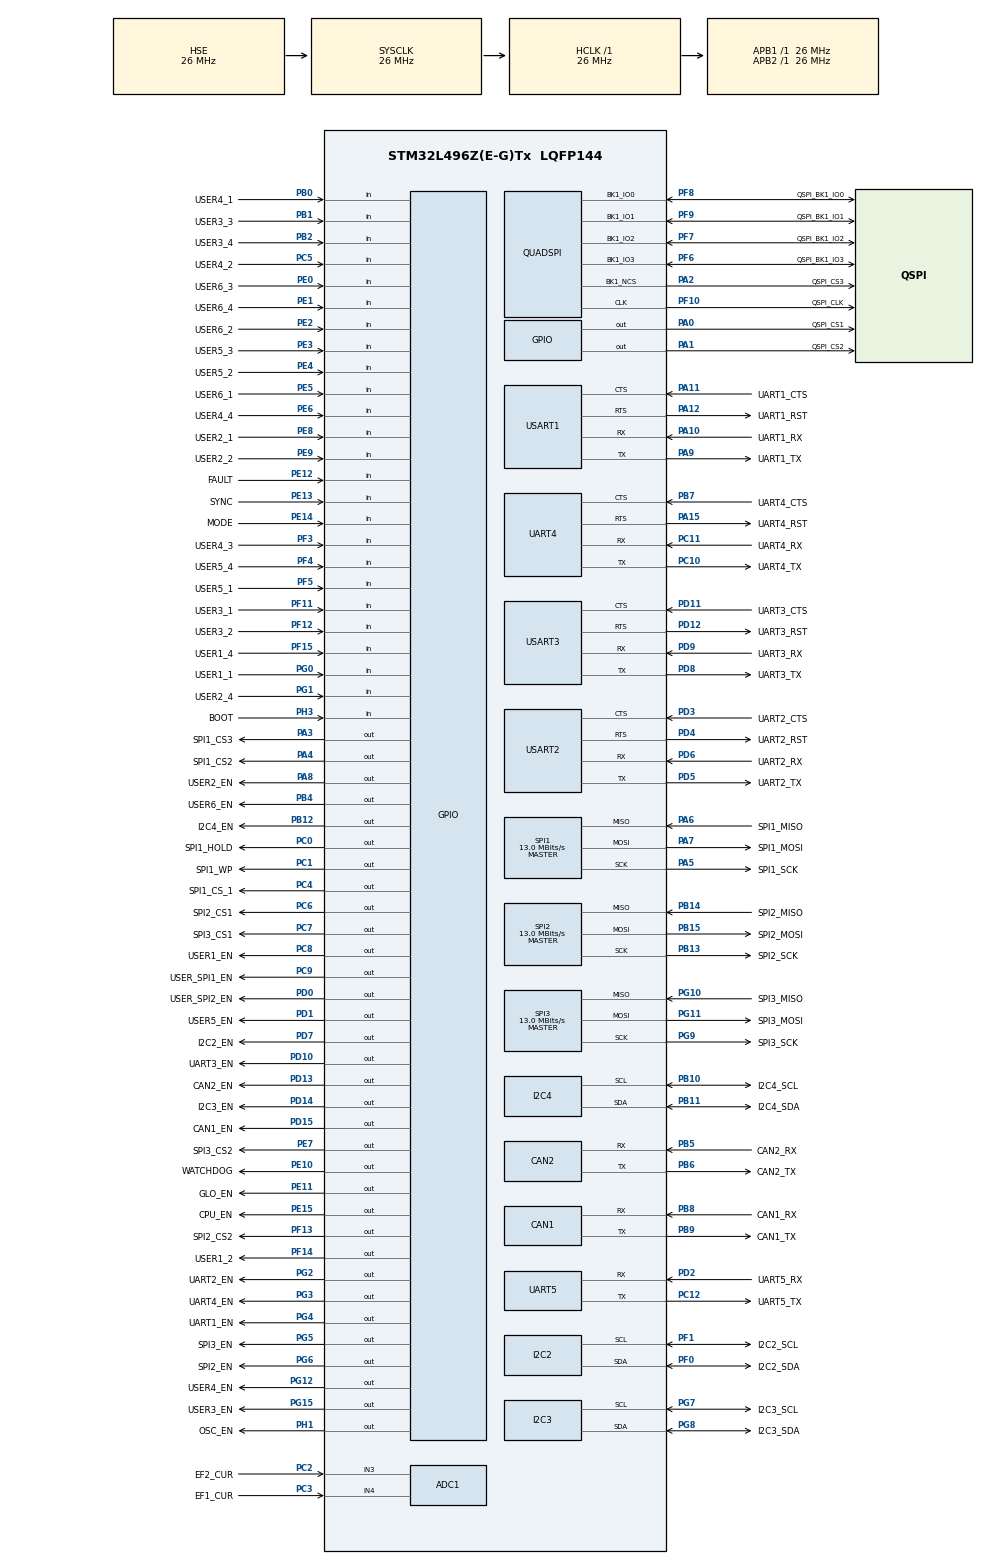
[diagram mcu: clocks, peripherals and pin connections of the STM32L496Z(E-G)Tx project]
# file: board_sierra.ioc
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ADC1.Channel-1\#ChannelRegularConversion=ADC_CHANNEL_3
ADC1.NbrOfConversionFlag=1
ADC1.OffsetNumber-1\#ChannelRegularConversion=ADC_OFFSET_NONE
ADC1.Rank-1\#ChannelRegularConversion=1
ADC1.SamplingTime-1\#ChannelRegularConversion=ADC_SAMPLETIME_2CYCLES_5
ADC1.master=1
CAN1.BS1=CAN_BS1_10TQ
CAN1.BS2=CAN_BS2_1TQ
CAN1.CalculateTimeQuantum=615.3846153846154
CAN2.BS1=CAN_BS1_10TQ
CAN2.BS2=CAN_BS2_1TQ
CAN2.CalculateTimeQuantum=615.3846153846154
I2C2.Timing=0x00606497
I2C3.Timing=0x00606497
I2C4.Timing=0x00606497
Mcu.Family=STM32L4
Mcu.Name=STM32L496Z(E-G)Tx
Mcu.Package=LQFP144
NVIC.PriorityGroup=NVIC_PRIORITYGROUP_4
PA0.GPIO_Label=QSPI_CS1
PA0.Signal=GPIO_Output
PA1.GPIO_Label=QSPI_CS2
PA1.Signal=GPIO_Output
PA10.GPIO_Label=UART1_RX
PA10.Mode=Asynchronous
PA10.Signal=USART1_RX
PA11.GPIO_Label=UART1_CTS
PA11.Mode=CTS_RTS
PA11.Signal=USART1_CTS
PA12.GPIO_Label=UART1_RST
PA12.Mode=CTS_RTS
PA12.Signal=USART1_RTS
PA13\ (JTMS/SWDIO).GPIO_Label=SW_DIO
PA13\ (JTMS/SWDIO).Mode=Trace_Asynchronous_SW
PA13\ (JTMS/SWDIO).Signal=SYS_JTMS-SWDIO
PA14\ (JTCK/SWCLK).GPIO_Label=SW_CLK
PA14\ (JTCK/SWCLK).Mode=Trace_Asynchronous_SW
PA14\ (JTCK/SWCLK).Signal=SYS_JTCK-SWCLK
PA15\ (JTDI).GPIO_Label=UART4_RST
PA15\ (JTDI).Mode=CTS_RTS
PA15\ (JTDI).Signal=UART4_RTS
PA2.GPIO_Label=QSPI_CS3
PA2.Mode=Single Bank 1
PA2.Signal=QUADSPI_BK1_NCS
PA3.GPIO_Label=SPI1_CS3
PA3.Signal=GPIO_Output
PA4.GPIO_Label=SPI1_CS2
PA4.Signal=GPIO_Output
PA5.GPIO_Label=SPI1_SCK
PA5.Mode=Full_Duplex_Master
PA5.Signal=SPI1_SCK
PA6.GPIO_Label=SPI1_MISO
PA6.Mode=Full_Duplex_Master
PA6.Signal=SPI1_MISO
PA7.GPIO_Label=SPI1_MOSI
PA7.Mode=Full_Duplex_Master
PA7.Signal=SPI1_MOSI
PA8.GPIO_Label=USER2_EN
PA8.Signal=GPIO_Output
PA9.GPIO_Label=UART1_TX
PA9.Mode=Asynchronous
PA9.Signal=USART1_TX
PB0.GPIO_Label=USER4_1
PB0.Signal=GPIO_Input
PB1.GPIO_Label=USER3_3
PB1.Signal=GPIO_Input
PB10.GPIO_Label=I2C4_SCL
PB10.Mode=I2C
PB10.Signal=I2C4_SCL
PB11.GPIO_Label=I2C4_SDA
PB11.Mode=I2C
PB11.Signal=I2C4_SDA
PB12.GPIO_Label=I2C4_EN
PB12.Signal=GPIO_Output
PB13.GPIO_Label=SPI2_SCK
PB13.Mode=Full_Duplex_Master
PB13.Signal=SPI2_SCK
PB14.GPIO_Label=SPI2_MISO
PB14.Mode=Full_Duplex_Master
PB14.Signal=SPI2_MISO
PB15.GPIO_Label=SPI2_MOSI
PB15.Mode=Full_Duplex_Master
PB15.Signal=SPI2_MOSI
PB2.GPIO_Label=USER3_4
PB2.Signal=GPIO_Input
PB3\ (JTDO/TRACESWO).GPIO_Label=SW_O
PB3\ (JTDO/TRACESWO).Mode=Trace_Asynchronous_SW
PB3\ (JTDO/TRACESWO).Signal=SYS_JTDO-SWO
PB4\ (NJTRST).GPIO_Label=USER6_EN
PB4\ (NJTRST).Signal=GPIO_Output
PB5.GPIO_Label=CAN2_RX
PB5.Mode=Slave
PB5.Signal=CAN2_RX
PB6.GPIO_Label=CAN2_TX
PB6.Mode=Slave
PB6.Signal=CAN2_TX
PB7.GPIO_Label=UART4_CTS
PB7.Mode=CTS_RTS
PB7.Signal=UART4_CTS
PB8.GPIO_Label=CAN1_RX
PB8.Mode=Master
PB8.Signal=CAN1_RX
PB9.GPIO_Label=CAN1_TX
PB9.Mode=Master
PB9.Signal=CAN1_TX
PC0.GPIO_Label=SPI1_HOLD
PC0.Signal=GPIO_Output
PC1.GPIO_Label=SPI1_WP
PC1.Signal=GPIO_Output
PC10.GPIO_Label=UART4_TX
PC10.Mode=Asynchronous
PC10.Signal=UART4_TX
PC11.GPIO_Label=UART4_RX
PC11.Mode=Asynchronous
PC11.Signal=UART4_RX
PC12.GPIO_Label=UART5_TX
PC12.Mode=Asynchronous
PC12.Signal=UART5_TX
PC14-OSC32_IN\ (PC14).GPIO_Label=OSC32_IN
PC14-OSC32_IN\ (PC14).Mode=LSE-External-Oscillator
PC14-OSC32_IN\ (PC14).Signal=RCC_OSC32_IN
PC15-OSC32_OUT\ (PC15).GPIO_Label=OSC32_OUT
PC15-OSC32_OUT\ (PC15).Mode=LSE-External-Oscillator
PC15-OSC32_OUT\ (PC15).Signal=RCC_OSC32_OUT
PC2.GPIO_Label=EF2_CUR
PC2.Signal=ADCx_IN3
PC3.GPIO_Label=EF1_CUR
PC3.Signal=ADCx_IN4
PC4.GPIO_Label=SPI1_CS_1
PC4.Signal=GPIO_Output
PC5.GPIO_Label=USER4_2
PC5.Signal=GPIO_Input
PC6.GPIO_Label=SPI2_CS1
PC6.Signal=GPIO_Output
PC7.GPIO_Label=SPI3_CS1
PC7.Signal=GPIO_Output
PC8.GPIO_Label=USER1_EN
PC8.Signal=GPIO_Output
PC9.GPIO_Label=USER_SPI1_EN
PC9.Signal=GPIO_Output
PD0.GPIO_Label=USER_SPI2_EN
PD0.Signal=GPIO_Output
PD1.GPIO_Label=USER5_EN
PD1.Signal=GPIO_Output
PD10.GPIO_Label=UART3_EN
PD10.Signal=GPIO_Output
PD11.GPIO_Label=UART3_CTS
PD11.Mode=CTS_RTS
PD11.Signal=USART3_CTS
PD12.GPIO_Label=UART3_RST
PD12.Mode=CTS_RTS
PD12.Signal=USART3_RTS
PD13.GPIO_Label=CAN2_EN
PD13.Signal=GPIO_Output
PD14.GPIO_Label=I2C3_EN
PD14.Signal=GPIO_Output
PD15.GPIO_Label=CAN1_EN
PD15.Signal=GPIO_Output
PD2.GPIO_Label=UART5_RX
PD2.Mode=Asynchronous
PD2.Signal=UART5_RX
PD3.GPIO_Label=UART2_CTS
PD3.Mode=CTS_RTS
PD3.Signal=USART2_CTS
PD4.GPIO_Label=UART2_RST
PD4.Mode=CTS_RTS
PD4.Signal=USART2_RTS
PD5.GPIO_Label=UART2_TX
PD5.Mode=Asynchronous
PD5.Signal=USART2_TX
PD6.GPIO_Label=UART2_RX
PD6.Mode=Asynchronous
PD6.Signal=USART2_RX
PD7.GPIO_Label=I2C2_EN
PD7.Signal=GPIO_Output
PD8.GPIO_Label=UART3_TX
PD8.Mode=Asynchronous
PD8.Signal=USART3_TX
PD9.GPIO_Label=UART3_RX
PD9.Mode=Asynchronous
PD9.Signal=USART3_RX
PE0.GPIO_Label=USER6_3
PE0.Signal=GPIO_Input
PE1.GPIO_Label=USER6_4
PE1.Signal=GPIO_Input
PE10.GPIO_Label=WATCHDOG
PE10.Signal=GPIO_Output
PE11.GPIO_Label=GLO_EN
PE11.Signal=GPIO_Output
PE12.GPIO_Label=FAULT
PE12.Signal=GPIO_Input
PE13.GPIO_Label=SYNC
PE13.Signal=GPIO_Input
PE14.GPIO_Label=MODE
PE14.Signal=GPIO_Input
PE15.GPIO_Label=CPU_EN
PE15.Signal=GPIO_Output
PE2.GPIO_Label=USER6_2
PE2.Signal=GPIO_Input
PE3.GPIO_Label=USER5_3
PE3.Signal=GPIO_Input
PE4.GPIO_Label=USER5_2
PE4.Signal=GPIO_Input
PE5.GPIO_Label=USER6_1
PE5.Signal=GPIO_Input
PE6.GPIO_Label=USER4_4
PE6.Signal=GPIO_Input
PE7.GPIO_Label=SPI3_CS2
PE7.Signal=GPIO_Output
PE8.GPIO_Label=USER2_1
PE8.Signal=GPIO_Input
PE9.GPIO_Label=USER2_2
PE9.Signal=GPIO_Input
PF0.GPIO_Label=I2C2_SDA
PF0.Mode=I2C
PF0.Signal=I2C2_SDA
PF1.GPIO_Label=I2C2_SCL
PF1.Mode=I2C
PF1.Signal=I2C2_SCL
PF10.GPIO_Label=QSPI_CLK
PF10.Mode=Single Bank 1
PF10.Signal=QUADSPI_CLK
PF11.GPIO_Label=USER3_1
PF11.Signal=GPIO_Input
PF12.GPIO_Label=USER3_2
PF12.Signal=GPIO_Input
PF13.GPIO_Label=SPI2_CS2
PF13.Signal=GPIO_Output
PF14.GPIO_Label=USER1_2
PF14.GPIO_Speed=GPIO_SPEED_FREQ_LOW
PF14.PinState=GPIO_PIN_RESET
PF14.Signal=GPIO_Output
PF15.GPIO_Label=USER1_4
PF15.Signal=GPIO_Input
PF3.GPIO_Label=USER4_3
PF3.Signal=GPIO_Input
PF4.GPIO_Label=USER5_4
PF4.Signal=GPIO_Input
PF5.GPIO_Label=USER5_1
PF5.Signal=GPIO_Input
PF6.GPIO_Label=QSPI_BK1_IO3
PF6.Mode=Single Bank 1
PF6.Signal=QUADSPI_BK1_IO3
PF7.GPIO_Label=QSPI_BK1_IO2
PF7.Mode=Single Bank 1
PF7.Signal=QUADSPI_BK1_IO2
PF8.GPIO_Label=QSPI_BK1_IO0
PF8.Mode=Single Bank 1
PF8.Signal=QUADSPI_BK1_IO0
PF9.GPIO_Label=QSPI_BK1_IO1
PF9.Mode=Single Bank 1
PF9.Signal=QUADSPI_BK1_IO1
PG0.GPIO_Label=USER1_1
PG0.Signal=GPIO_Input
PG1.GPIO_Label=USER2_4
PG1.Signal=GPIO_Input
PG10.GPIO_Label=SPI3_MISO
PG10.Mode=Full_Duplex_Master
PG10.Signal=SPI3_MISO
PG11.GPIO_Label=SPI3_MOSI
PG11.Mode=Full_Duplex_Master
PG11.Signal=SPI3_MOSI
PG12.GPIO_Label=USER4_EN
PG12.Signal=GPIO_Output
PG15.GPIO_Label=USER3_EN
PG15.Signal=GPIO_Output
PG2.GPIO_Label=UART2_EN
PG2.Signal=GPIO_Output
PG3.GPIO_Label=UART4_EN
PG3.Signal=GPIO_Output
PG4.GPIO_Label=UART1_EN
PG4.Signal=GPIO_Output
PG5.GPIO_Label=SPI3_EN
PG5.Signal=GPIO_Output
PG6.GPIO_Label=SPI2_EN
PG6.Signal=GPIO_Output
PG7.GPIO_Label=I2C3_SCL
PG7.Mode=I2C
PG7.Signal=I2C3_SCL
PG8.GPIO_Label=I2C3_SDA
PG8.Mode=I2C
PG8.Signal=I2C3_SDA
PG9.GPIO_Label=SPI3_SCK
PG9.Mode=Full_Duplex_Master
PG9.Signal=SPI3_SCK
PH0-OSC_IN\ (PH0).GPIO_Label=OSC_IN
PH0-OSC_IN\ (PH0).Mode=HSE-External-Clock-Source
PH0-OSC_IN\ (PH0).Signal=RCC_OSC_IN
PH1-OSC_OUT\ (PH1).GPIO_Label=OSC_EN
PH1-OSC_OUT\ (PH1).GPIO_PuPd=GPIO_PULLUP
PH1-OSC_OUT\ (PH1).PinState=GPIO_PIN_SET
PH1-OSC_OUT\ (PH1).Signal=GPIO_Output
PH3-BOOT0.GPIO_Label=BOOT
PH3-BOOT0.Signal=GPIO_Input
ProjectManager.HeapSize=0x200
ProjectManager.StackSize=0x400
ProjectManager.TargetToolchain=STM32CubeIDE
RCC.ADCFreq_Value=64000000
RCC.AHBFreq_Value=26000000
RCC.APB1Freq_Value=26000000
RCC.APB1TimFreq_Value=26000000
RCC.APB2Freq_Value=26000000
RCC.APB2TimFreq_Value=26000000
RCC.CortexFreq_Value=26000000
RCC.HCLKFreq_Value=26000000
RCC.HSE_VALUE=26000000
RCC.HSI48_VALUE=48000000
RCC.HSI_VALUE=16000000
RCC.MSI_VALUE=4000000
RCC.PLLN=12
RCC.PLLR=RCC_PLLR_DIV4
RCC.PLLSAI1N=16
RCC.PLLSAI1R=RCC_PLLR_DIV4
RCC.PLLSourceVirtual=RCC_PLLSOURCE_HSI
RCC.SYSCLKFreq_VALUE=26000000
RCC.SYSCLKSource=RCC_SYSCLKSOURCE_HSE
RCC.USBFreq_Value=128000000
RCC.VCOOutputFreq_Value=192000000
SH.ADCx_IN3.0=ADC1_IN3,IN3-Single-Ended
SH.ADCx_IN4.0=ADC1_IN4,IN4-Single-Ended
SPI1.BaudRatePrescaler=SPI_BAUDRATEPRESCALER_2
SPI1.CalculateBaudRate=13.0 MBits/s
SPI1.Direction=SPI_DIRECTION_2LINES
SPI1.Mode=SPI_MODE_MASTER
SPI1.VirtualType=VM_MASTER
SPI2.BaudRatePrescaler=SPI_BAUDRATEPRESCALER_2
SPI2.CalculateBaudRate=13.0 MBits/s
SPI2.Direction=SPI_DIRECTION_2LINES
SPI2.Mode=SPI_MODE_MASTER
SPI2.VirtualType=VM_MASTER
SPI3.BaudRatePrescaler=SPI_BAUDRATEPRESCALER_2
SPI3.CalculateBaudRate=13.0 MBits/s
SPI3.Direction=SPI_DIRECTION_2LINES
SPI3.Mode=SPI_MODE_MASTER
SPI3.VirtualType=VM_MASTER
USART1.VirtualMode-Asynchronous=VM_ASYNC
USART2.VirtualMode-Asynchronous=VM_ASYNC
USART3.VirtualMode-Asynchronous=VM_ASYNC
VP_RCC_LSE.Mode=CRS SYNC Source LSE
VP_SYS_V_PVD_IN.Mode=Mode_PVD_Int
board=custom

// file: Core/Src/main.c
/* USER CODE BEGIN Header */
/**
  ******************************************************************************
  * @file           : main.c
  * @brief          : Main program body
  ******************************************************************************
  * @attention
  *
  * <h2><center>&copy; Copyright (c) 2020 STMicroelectronics.
  * All rights reserved.</center></h2>
  *
  * This software component is licensed by ST under BSD 3-Clause license,
  * the "License"; You may not use this file except in compliance with the
  * License. You may obtain a copy of the License at:
  *                        opensource.org/licenses/BSD-3-Clause
  *
  ******************************************************************************
  */
/* USER CODE END Header */

#include "main.h"

ADC_HandleTypeDef hadc1;

CAN_HandleTypeDef hcan1;
CAN_HandleTypeDef hcan2;

I2C_HandleTypeDef hi2c2;
I2C_HandleTypeDef hi2c3;
I2C_HandleTypeDef hi2c4;

QSPI_HandleTypeDef hqspi;

SPI_HandleTypeDef hspi1;
SPI_HandleTypeDef hspi2;
SPI_HandleTypeDef hspi3;

UART_HandleTypeDef huart4;
UART_HandleTypeDef huart5;
UART_HandleTypeDef huart1;
UART_HandleTypeDef huart2;
UART_HandleTypeDef huart3;

void SystemClock_Config(void);
static void MX_GPIO_Init(void);
static void MX_ADC1_Init(void);
static void MX_CAN1_Init(void);
static void MX_CAN2_Init(void);
static void MX_I2C2_Init(void);
static void MX_I2C3_Init(void);
static void MX_I2C4_Init(void);
static void MX_QUADSPI_Init(void);
static void MX_SPI1_Init(void);
static void MX_SPI2_Init(void);
static void MX_SPI3_Init(void);
static void MX_UART4_Init(void);
static void MX_UART5_Init(void);
static void MX_USART1_UART_Init(void);
static void MX_USART2_UART_Init(void);
static void MX_USART3_UART_Init(void);

int main(void)
{

  /* MCU Configuration--------------------------------------------------------*/

  /* Reset of all peripherals, Initializes the Flash interface and the Systick. */
  HAL_Init();

  /* Configure the system clock */
  SystemClock_Config();

  /* Initialize all configured peripherals */
  MX_GPIO_Init();
  MX_ADC1_Init();
  MX_CAN1_Init();
  MX_CAN2_Init();
  MX_I2C2_Init();
  MX_I2C3_Init();
  MX_I2C4_Init();
  MX_QUADSPI_Init();
  MX_SPI1_Init();
  MX_SPI2_Init();
  MX_SPI3_Init();
  MX_UART4_Init();
  MX_UART5_Init();
  MX_USART1_UART_Init();
  MX_USART2_UART_Init();
  MX_USART3_UART_Init();
  /* USER CODE BEGIN 2 */

  // turn on isolator for USER1
  HAL_GPIO_WritePin(GPIOC, USER1_EN_Pin, GPIO_PIN_SET);

  /* USER CODE END 2 */

  /* Infinite loop */
  /* USER CODE BEGIN WHILE */
  while (1)
  {

	  HAL_GPIO_TogglePin(GPIOF, USER1_2_Pin);
	  HAL_Delay(200);

    /* USER CODE END WHILE */

  }
}

void SystemClock_Config(void)
{
  RCC_OscInitTypeDef RCC_OscInitStruct = {0};
  RCC_ClkInitTypeDef RCC_ClkInitStruct = {0};
  RCC_PeriphCLKInitTypeDef PeriphClkInit = {0};
  RCC_CRSInitTypeDef RCC_CRSInitStruct = {0};

  /** Initializes the CPU, AHB and APB busses clocks
  */
  RCC_OscInitStruct.OscillatorType = RCC_OSCILLATORTYPE_HSI|RCC_OSCILLATORTYPE_HSE;
  RCC_OscInitStruct.HSEState = RCC_HSE_BYPASS;
  RCC_OscInitStruct.HSIState = RCC_HSI_ON;
  RCC_OscInitStruct.HSICalibrationValue = RCC_HSICALIBRATION_DEFAULT;
  RCC_OscInitStruct.PLL.PLLState = RCC_PLL_NONE;
  if (HAL_RCC_OscConfig(&RCC_OscInitStruct) != HAL_OK)
  {
    Error_Handler();
  }
  /** Initializes the CPU, AHB and APB busses clocks
  */
  RCC_ClkInitStruct.ClockType = RCC_CLOCKTYPE_HCLK|RCC_CLOCKTYPE_SYSCLK
                              |RCC_CLOCKTYPE_PCLK1|RCC_CLOCKTYPE_PCLK2;
  RCC_ClkInitStruct.SYSCLKSource = RCC_SYSCLKSOURCE_HSE;
  RCC_ClkInitStruct.AHBCLKDivider = RCC_SYSCLK_DIV1;
  RCC_ClkInitStruct.APB1CLKDivider = RCC_HCLK_DIV1;
  RCC_ClkInitStruct.APB2CLKDivider = RCC_HCLK_DIV1;

  if (HAL_RCC_ClockConfig(&RCC_ClkInitStruct, FLASH_LATENCY_1) != HAL_OK)
  {
    Error_Handler();
  }
  PeriphClkInit.PeriphClockSelection = RCC_PERIPHCLK_USART1|RCC_PERIPHCLK_USART2
                              |RCC_PERIPHCLK_USART3|RCC_PERIPHCLK_UART4
                              |RCC_PERIPHCLK_UART5|RCC_PERIPHCLK_I2C2
                              |RCC_PERIPHCLK_I2C3|RCC_PERIPHCLK_I2C4
                              |RCC_PERIPHCLK_ADC;
  PeriphClkInit.Usart1ClockSelection = RCC_USART1CLKSOURCE_PCLK2;
  PeriphClkInit.Usart2ClockSelection = RCC_USART2CLKSOURCE_PCLK1;
  PeriphClkInit.Usart3ClockSelection = RCC_USART3CLKSOURCE_PCLK1;
  PeriphClkInit.Uart4ClockSelection = RCC_UART4CLKSOURCE_PCLK1;
  PeriphClkInit.Uart5ClockSelection = RCC_UART5CLKSOURCE_PCLK1;
  PeriphClkInit.I2c2ClockSelection = RCC_I2C2CLKSOURCE_PCLK1;
  PeriphClkInit.I2c3ClockSelection = RCC_I2C3CLKSOURCE_PCLK1;
  PeriphClkInit.I2c4ClockSelection = RCC_I2C4CLKSOURCE_PCLK1;
  PeriphClkInit.AdcClockSelection = RCC_ADCCLKSOURCE_PLLSAI1;
  PeriphClkInit.PLLSAI1.PLLSAI1Source = RCC_PLLSOURCE_HSI;
  PeriphClkInit.PLLSAI1.PLLSAI1M = 1;
  PeriphClkInit.PLLSAI1.PLLSAI1N = 16;
  PeriphClkInit.PLLSAI1.PLLSAI1P = RCC_PLLP_DIV2;
  PeriphClkInit.PLLSAI1.PLLSAI1Q = RCC_PLLQ_DIV2;
  PeriphClkInit.PLLSAI1.PLLSAI1R = RCC_PLLR_DIV4;
  PeriphClkInit.PLLSAI1.PLLSAI1ClockOut = RCC_PLLSAI1_ADC1CLK;
  if (HAL_RCCEx_PeriphCLKConfig(&PeriphClkInit) != HAL_OK)
  {
    Error_Handler();
  }
  /** Configure the main internal regulator output voltage
  */
  if (HAL_PWREx_ControlVoltageScaling(PWR_REGULATOR_VOLTAGE_SCALE1) != HAL_OK)
  {
    Error_Handler();
  }
  /** Enable the SYSCFG APB clock
  */
  __HAL_RCC_CRS_CLK_ENABLE();
  /** Configures CRS
  */
  RCC_CRSInitStruct.Prescaler = RCC_CRS_SYNC_DIV1;
  RCC_CRSInitStruct.Source = RCC_CRS_SYNC_SOURCE_LSE;
  RCC_CRSInitStruct.Polarity = RCC_CRS_SYNC_POLARITY_RISING;
  RCC_CRSInitStruct.ReloadValue = __HAL_RCC_CRS_RELOADVALUE_CALCULATE(48000000,32768);
  RCC_CRSInitStruct.ErrorLimitValue = 34;
  RCC_CRSInitStruct.HSI48CalibrationValue = 32;

  HAL_RCCEx_CRSConfig(&RCC_CRSInitStruct);
}

static void MX_ADC1_Init(void)
{

  ADC_MultiModeTypeDef multimode = {0};
  ADC_ChannelConfTypeDef sConfig = {0};

  /** Common config
  */
  hadc1.Instance = ADC1;
  hadc1.Init.ClockPrescaler = ADC_CLOCK_ASYNC_DIV1;
  hadc1.Init.Resolution = ADC_RESOLUTION_12B;
  hadc1.Init.DataAlign = ADC_DATAALIGN_RIGHT;
  hadc1.Init.ScanConvMode = ADC_SCAN_DISABLE;
  hadc1.Init.EOCSelection = ADC_EOC_SINGLE_CONV;
  hadc1.Init.LowPowerAutoWait = DISABLE;
  hadc1.Init.ContinuousConvMode = DISABLE;
  hadc1.Init.NbrOfConversion = 1;
  hadc1.Init.DiscontinuousConvMode = DISABLE;
  hadc1.Init.NbrOfDiscConversion = 1;
  hadc1.Init.ExternalTrigConv = ADC_SOFTWARE_START;
  hadc1.Init.ExternalTrigConvEdge = ADC_EXTERNALTRIGCONVEDGE_NONE;
  hadc1.Init.DMAContinuousRequests = DISABLE;
  hadc1.Init.Overrun = ADC_OVR_DATA_PRESERVED;
  hadc1.Init.OversamplingMode = DISABLE;
  if (HAL_ADC_Init(&hadc1) != HAL_OK)
  {
    Error_Handler();
  }
  /** Configure the ADC multi-mode
  */
  multimode.Mode = ADC_MODE_INDEPENDENT;
  if (HAL_ADCEx_MultiModeConfigChannel(&hadc1, &multimode) != HAL_OK)
  {
    Error_Handler();
  }
  /** Configure Regular Channel
  */
  sConfig.Channel = ADC_CHANNEL_3;
  sConfig.Rank = ADC_REGULAR_RANK_1;
  sConfig.SamplingTime = ADC_SAMPLETIME_2CYCLES_5;
  sConfig.SingleDiff = ADC_SINGLE_ENDED;
  sConfig.OffsetNumber = ADC_OFFSET_NONE;
  sConfig.Offset = 0;
  if (HAL_ADC_ConfigChannel(&hadc1, &sConfig) != HAL_OK)
  {
    Error_Handler();
  }

}

static void MX_CAN1_Init(void)
{

  hcan1.Instance = CAN1;
  hcan1.Init.Prescaler = 16;
  hcan1.Init.Mode = CAN_MODE_NORMAL;
  hcan1.Init.SyncJumpWidth = CAN_SJW_1TQ;
  hcan1.Init.TimeSeg1 = CAN_BS1_10TQ;
  hcan1.Init.TimeSeg2 = CAN_BS2_1TQ;
  hcan1.Init.TimeTriggeredMode = DISABLE;
  hcan1.Init.AutoBusOff = DISABLE;
  hcan1.Init.AutoWakeUp = DISABLE;
  hcan1.Init.AutoRetransmission = DISABLE;
  hcan1.Init.ReceiveFifoLocked = DISABLE;
  hcan1.Init.TransmitFifoPriority = DISABLE;
  if (HAL_CAN_Init(&hcan1) != HAL_OK)
  {
    Error_Handler();
  }

}

static void MX_CAN2_Init(void)
{

  hcan2.Instance = CAN2;
  hcan2.Init.Prescaler = 16;
  hcan2.Init.Mode = CAN_MODE_NORMAL;
  hcan2.Init.SyncJumpWidth = CAN_SJW_1TQ;
  hcan2.Init.TimeSeg1 = CAN_BS1_10TQ;
  hcan2.Init.TimeSeg2 = CAN_BS2_1TQ;
  hcan2.Init.TimeTriggeredMode = DISABLE;
  hcan2.Init.AutoBusOff = DISABLE;
  hcan2.Init.AutoWakeUp = DISABLE;
  hcan2.Init.AutoRetransmission = DISABLE;
  hcan2.Init.ReceiveFifoLocked = DISABLE;
  hcan2.Init.TransmitFifoPriority = DISABLE;
  if (HAL_CAN_Init(&hcan2) != HAL_OK)
  {
    Error_Handler();
  }

}

static void MX_I2C2_Init(void)
{

  hi2c2.Instance = I2C2;
  hi2c2.Init.Timing = 0x00606497;
  hi2c2.Init.OwnAddress1 = 0;
  hi2c2.Init.AddressingMode = I2C_ADDRESSINGMODE_7BIT;
  hi2c2.Init.DualAddressMode = I2C_DUALADDRESS_DISABLE;
  hi2c2.Init.OwnAddress2 = 0;
  hi2c2.Init.OwnAddress2Masks = I2C_OA2_NOMASK;
  hi2c2.Init.GeneralCallMode = I2C_GENERALCALL_DISABLE;
  hi2c2.Init.NoStretchMode = I2C_NOSTRETCH_DISABLE;
  if (HAL_I2C_Init(&hi2c2) != HAL_OK)
  {
    Error_Handler();
  }
  /** Configure Analogue filter
  */
  if (HAL_I2CEx_ConfigAnalogFilter(&hi2c2, I2C_ANALOGFILTER_ENABLE) != HAL_OK)
  {
    Error_Handler();
  }
  /** Configure Digital filter
  */
  if (HAL_I2CEx_ConfigDigitalFilter(&hi2c2, 0) != HAL_OK)
  {
    Error_Handler();
  }

}

static void MX_I2C3_Init(void)
{

  hi2c3.Instance = I2C3;
  hi2c3.Init.Timing = 0x00606497;
  hi2c3.Init.OwnAddress1 = 0;
  hi2c3.Init.AddressingMode = I2C_ADDRESSINGMODE_7BIT;
  hi2c3.Init.DualAddressMode = I2C_DUALADDRESS_DISABLE;
  hi2c3.Init.OwnAddress2 = 0;
  hi2c3.Init.OwnAddress2Masks = I2C_OA2_NOMASK;
  hi2c3.Init.GeneralCallMode = I2C_GENERALCALL_DISABLE;
  hi2c3.Init.NoStretchMode = I2C_NOSTRETCH_DISABLE;
  if (HAL_I2C_Init(&hi2c3) != HAL_OK)
  {
    Error_Handler();
  }
  /** Configure Analogue filter
  */
  if (HAL_I2CEx_ConfigAnalogFilter(&hi2c3, I2C_ANALOGFILTER_ENABLE) != HAL_OK)
  {
    Error_Handler();
  }
  /** Configure Digital filter
  */
  if (HAL_I2CEx_ConfigDigitalFilter(&hi2c3, 0) != HAL_OK)
  {
    Error_Handler();
  }

}

static void MX_I2C4_Init(void)
{

  hi2c4.Instance = I2C4;
  hi2c4.Init.Timing = 0x00606497;
  hi2c4.Init.OwnAddress1 = 0;
  hi2c4.Init.AddressingMode = I2C_ADDRESSINGMODE_7BIT;
  hi2c4.Init.DualAddressMode = I2C_DUALADDRESS_DISABLE;
  hi2c4.Init.OwnAddress2 = 0;
  hi2c4.Init.OwnAddress2Masks = I2C_OA2_NOMASK;
  hi2c4.Init.GeneralCallMode = I2C_GENERALCALL_DISABLE;
  hi2c4.Init.NoStretchMode = I2C_NOSTRETCH_DISABLE;
  if (HAL_I2C_Init(&hi2c4) != HAL_OK)
  {
    Error_Handler();
  }
  /** Configure Analogue filter
  */
  if (HAL_I2CEx_ConfigAnalogFilter(&hi2c4, I2C_ANALOGFILTER_ENABLE) != HAL_OK)
  {
    Error_Handler();
  }
  /** Configure Digital filter
  */
  if (HAL_I2CEx_ConfigDigitalFilter(&hi2c4, 0) != HAL_OK)
  {
    Error_Handler();
  }

}

static void MX_QUADSPI_Init(void)
{

  /* QUADSPI parameter configuration*/
  hqspi.Instance = QUADSPI;
  hqspi.Init.ClockPrescaler = 255;
  hqspi.Init.FifoThreshold = 1;
  hqspi.Init.SampleShifting = QSPI_SAMPLE_SHIFTING_NONE;
  hqspi.Init.FlashSize = 1;
  hqspi.Init.ChipSelectHighTime = QSPI_CS_HIGH_TIME_1_CYCLE;
  hqspi.Init.ClockMode = QSPI_CLOCK_MODE_0;
  hqspi.Init.FlashID = QSPI_FLASH_ID_1;
  hqspi.Init.DualFlash = QSPI_DUALFLASH_DISABLE;
  if (HAL_QSPI_Init(&hqspi) != HAL_OK)
  {
    Error_Handler();
  }

}

static void MX_SPI1_Init(void)
{

  /* SPI1 parameter configuration*/
  hspi1.Instance = SPI1;
  hspi1.Init.Mode = SPI_MODE_MASTER;
  hspi1.Init.Direction = SPI_DIRECTION_2LINES;
  hspi1.Init.DataSize = SPI_DATASIZE_4BIT;
  hspi1.Init.CLKPolarity = SPI_POLARITY_LOW;
  hspi1.Init.CLKPhase = SPI_PHASE_1EDGE;
  hspi1.Init.NSS = SPI_NSS_SOFT;
  hspi1.Init.BaudRatePrescaler = SPI_BAUDRATEPRESCALER_2;
  hspi1.Init.FirstBit = SPI_FIRSTBIT_MSB;
  hspi1.Init.TIMode = SPI_TIMODE_DISABLE;
  hspi1.Init.CRCCalculation = SPI_CRCCALCULATION_DISABLE;
  hspi1.Init.CRCPolynomial = 7;
  hspi1.Init.CRCLength = SPI_CRC_LENGTH_DATASIZE;
  hspi1.Init.NSSPMode = SPI_NSS_PULSE_ENABLE;
  if (HAL_SPI_Init(&hspi1) != HAL_OK)
  {
    Error_Handler();
  }

}

static void MX_SPI2_Init(void)
{

  /* SPI2 parameter configuration*/
  hspi2.Instance = SPI2;
  hspi2.Init.Mode = SPI_MODE_MASTER;
  hspi2.Init.Direction = SPI_DIRECTION_2LINES;
  hspi2.Init.DataSize = SPI_DATASIZE_4BIT;
  hspi2.Init.CLKPolarity = SPI_POLARITY_LOW;
  hspi2.Init.CLKPhase = SPI_PHASE_1EDGE;
  hspi2.Init.NSS = SPI_NSS_SOFT;
  hspi2.Init.BaudRatePrescaler = SPI_BAUDRATEPRESCALER_2;
  hspi2.Init.FirstBit = SPI_FIRSTBIT_MSB;
  hspi2.Init.TIMode = SPI_TIMODE_DISABLE;
  hspi2.Init.CRCCalculation = SPI_CRCCALCULATION_DISABLE;
  hspi2.Init.CRCPolynomial = 7;
  hspi2.Init.CRCLength = SPI_CRC_LENGTH_DATASIZE;
  hspi2.Init.NSSPMode = SPI_NSS_PULSE_ENABLE;
  if (HAL_SPI_Init(&hspi2) != HAL_OK)
  {
    Error_Handler();
  }

}

static void MX_SPI3_Init(void)
{

  /* SPI3 parameter configuration*/
  hspi3.Instance = SPI3;
  hspi3.Init.Mode = SPI_MODE_MASTER;
  hspi3.Init.Direction = SPI_DIRECTION_2LINES;
  hspi3.Init.DataSize = SPI_DATASIZE_4BIT;
  hspi3.Init.CLKPolarity = SPI_POLARITY_LOW;
  hspi3.Init.CLKPhase = SPI_PHASE_1EDGE;
  hspi3.Init.NSS = SPI_NSS_SOFT;
  hspi3.Init.BaudRatePrescaler = SPI_BAUDRATEPRESCALER_2;
  hspi3.Init.FirstBit = SPI_FIRSTBIT_MSB;
  hspi3.Init.TIMode = SPI_TIMODE_DISABLE;
  hspi3.Init.CRCCalculation = SPI_CRCCALCULATION_DISABLE;
  hspi3.Init.CRCPolynomial = 7;
  hspi3.Init.CRCLength = SPI_CRC_LENGTH_DATASIZE;
  hspi3.Init.NSSPMode = SPI_NSS_PULSE_ENABLE;
  if (HAL_SPI_Init(&hspi3) != HAL_OK)
  {
    Error_Handler();
  }

}

static void MX_UART4_Init(void)
{

  huart4.Instance = UART4;
  huart4.Init.BaudRate = 115200;
  huart4.Init.WordLength = UART_WORDLENGTH_8B;
  huart4.Init.StopBits = UART_STOPBITS_1;
  huart4.Init.Parity = UART_PARITY_NONE;
  huart4.Init.Mode = UART_MODE_TX_RX;
  huart4.Init.HwFlowCtl = UART_HWCONTROL_RTS_CTS;
  huart4.Init.OverSampling = UART_OVERSAMPLING_16;
  huart4.Init.OneBitSampling = UART_ONE_BIT_SAMPLE_DISABLE;
  huart4.AdvancedInit.AdvFeatureInit = UART_ADVFEATURE_NO_INIT;
  if (HAL_UART_Init(&huart4) != HAL_OK)
  {
    Error_Handler();
  }

}

static void MX_UART5_Init(void)
{

  huart5.Instance = UART5;
  huart5.Init.BaudRate = 115200;
  huart5.Init.WordLength = UART_WORDLENGTH_8B;
  huart5.Init.StopBits = UART_STOPBITS_1;
  huart5.Init.Parity = UART_PARITY_NONE;
  huart5.Init.Mode = UART_MODE_TX_RX;
  huart5.Init.HwFlowCtl = UART_HWCONTROL_NONE;
  huart5.Init.OverSampling = UART_OVERSAMPLING_16;
  huart5.Init.OneBitSampling = UART_ONE_BIT_SAMPLE_DISABLE;
  huart5.AdvancedInit.AdvFeatureInit = UART_ADVFEATURE_NO_INIT;
  if (HAL_UART_Init(&huart5) != HAL_OK)
  {
    Error_Handler();
  }

}

static void MX_USART1_UART_Init(void)
{

  huart1.Instance = USART1;
  huart1.Init.BaudRate = 115200;
  huart1.Init.WordLength = UART_WORDLENGTH_8B;
  huart1.Init.StopBits = UART_STOPBITS_1;
  huart1.Init.Parity = UART_PARITY_NONE;
  huart1.Init.Mode = UART_MODE_TX_RX;
  huart1.Init.HwFlowCtl = UART_HWCONTROL_RTS_CTS;
  huart1.Init.OverSampling = UART_OVERSAMPLING_16;
  huart1.Init.OneBitSampling = UART_ONE_BIT_SAMPLE_DISABLE;
  huart1.AdvancedInit.AdvFeatureInit = UART_ADVFEATURE_NO_INIT;
  if (HAL_UART_Init(&huart1) != HAL_OK)
  {
    Error_Handler();
  }

}

static void MX_USART2_UART_Init(void)
{

  huart2.Instance = USART2;
  huart2.Init.BaudRate = 115200;
  huart2.Init.WordLength = UART_WORDLENGTH_8B;
  huart2.Init.StopBits = UART_STOPBITS_1;
  huart2.Init.Parity = UART_PARITY_NONE;
  huart2.Init.Mode = UART_MODE_TX_RX;
  huart2.Init.HwFlowCtl = UART_HWCONTROL_RTS_CTS;
  huart2.Init.OverSampling = UART_OVERSAMPLING_16;
  huart2.Init.OneBitSampling = UART_ONE_BIT_SAMPLE_DISABLE;
  huart2.AdvancedInit.AdvFeatureInit = UART_ADVFEATURE_NO_INIT;
  if (HAL_UART_Init(&huart2) != HAL_OK)
  {
    Error_Handler();
  }

}

static void MX_USART3_UART_Init(void)
{

  huart3.Instance = USART3;
  huart3.Init.BaudRate = 115200;
  huart3.Init.WordLength = UART_WORDLENGTH_8B;
  huart3.Init.StopBits = UART_STOPBITS_1;
  huart3.Init.Parity = UART_PARITY_NONE;
  huart3.Init.Mode = UART_MODE_TX_RX;
  huart3.Init.HwFlowCtl = UART_HWCONTROL_RTS_CTS;
  huart3.Init.OverSampling = UART_OVERSAMPLING_16;
  huart3.Init.OneBitSampling = UART_ONE_BIT_SAMPLE_DISABLE;
  huart3.AdvancedInit.AdvFeatureInit = UART_ADVFEATURE_NO_INIT;
  if (HAL_UART_Init(&huart3) != HAL_OK)
  {
    Error_Handler();
  }

}

static void MX_GPIO_Init(void)
{
  GPIO_InitTypeDef GPIO_InitStruct = {0};

  /* GPIO Ports Clock Enable */
  __HAL_RCC_GPIOE_CLK_ENABLE();
  __HAL_RCC_GPIOC_CLK_ENABLE();
  __HAL_RCC_GPIOF_CLK_ENABLE();
  __HAL_RCC_GPIOH_CLK_ENABLE();
  __HAL_RCC_GPIOA_CLK_ENABLE();
  __HAL_RCC_GPIOB_CLK_ENABLE();
  __HAL_RCC_GPIOG_CLK_ENABLE();
  __HAL_RCC_GPIOD_CLK_ENABLE();
  HAL_PWREx_EnableVddIO2();

  /*Configure GPIO pin Output Level */
  HAL_GPIO_WritePin(OSC_EN_GPIO_Port, OSC_EN_Pin, GPIO_PIN_SET);

  /*Configure GPIO pin Output Level */
  HAL_GPIO_WritePin(GPIOC, SPI1_HOLD_Pin|SPI1_WP_Pin|SPI1_CS_1_Pin|SPI2_CS1_Pin
                          |SPI3_CS1_Pin|USER1_EN_Pin|USER_SPI1_EN_Pin, GPIO_PIN_RESET);

  /*Configure GPIO pin Output Level */
  HAL_GPIO_WritePin(GPIOA, QSPI_CS1_Pin|QSPI_CS2_Pin|SPI1_CS3_Pin|SPI1_CS2_Pin
                          |USER2_EN_Pin, GPIO_PIN_RESET);

  /*Configure GPIO pin Output Level */
  HAL_GPIO_WritePin(GPIOF, SPI2_CS2_Pin|USER1_2_Pin, GPIO_PIN_RESET);

  /*Configure GPIO pin Output Level */
  HAL_GPIO_WritePin(GPIOE, SPI3_CS2_Pin|WATCHDOG_Pin|GLO_EN_Pin|CPU_EN_Pin, GPIO_PIN_RESET);

  /*Configure GPIO pin Output Level */
  HAL_GPIO_WritePin(GPIOB, I2C4_EN_Pin|USER6_EN_Pin, GPIO_PIN_RESET);

  /*Configure GPIO pin Output Level */
  HAL_GPIO_WritePin(GPIOD, UART3_EN_Pin|CAN2_EN_Pin|I2C3_EN_Pin|CAN1_EN_Pin
                          |USER_SPI2_EN_Pin|USER5_EN_Pin|I2C2_EN_Pin, GPIO_PIN_RESET);

  /*Configure GPIO pin Output Level */
  HAL_GPIO_WritePin(GPIOG, UART2_EN_Pin|UART4_EN_Pin|UART1_EN_Pin|SPI3_EN_Pin
                          |SPI2_EN_Pin|USER4_EN_Pin|USER3_EN_Pin, GPIO_PIN_RESET);

  /*Configure GPIO pins : USER6_2_Pin USER5_3_Pin USER5_2_Pin USER6_1_Pin
                           USER4_4_Pin USER2_1_Pin USER2_2_Pin FAULT_Pin
                           SYNC_Pin MODE_Pin USER6_3_Pin USER6_4_Pin */
  GPIO_InitStruct.Pin = USER6_2_Pin|USER5_3_Pin|USER5_2_Pin|USER6_1_Pin
                          |USER4_4_Pin|USER2_1_Pin|USER2_2_Pin|FAULT_Pin
                          |SYNC_Pin|MODE_Pin|USER6_3_Pin|USER6_4_Pin;
  GPIO_InitStruct.Mode = GPIO_MODE_INPUT;
  GPIO_InitStruct.Pull = GPIO_NOPULL;
  HAL_GPIO_Init(GPIOE, &GPIO_InitStruct);

  /*Configure GPIO pins : USER4_3_Pin USER5_4_Pin USER5_1_Pin USER3_1_Pin
                           USER3_2_Pin USER1_4_Pin */
  GPIO_InitStruct.Pin = USER4_3_Pin|USER5_4_Pin|USER5_1_Pin|USER3_1_Pin
                          |USER3_2_Pin|USER1_4_Pin;
  GPIO_InitStruct.Mode = GPIO_MODE_INPUT;
  GPIO_InitStruct.Pull = GPIO_NOPULL;
  HAL_GPIO_Init(GPIOF, &GPIO_InitStruct);

  /*Configure GPIO pin : OSC_EN_Pin */
  GPIO_InitStruct.Pin = OSC_EN_Pin;
  GPIO_InitStruct.Mode = GPIO_MODE_OUTPUT_PP;
  GPIO_InitStruct.Pull = GPIO_PULLUP;
  GPIO_InitStruct.Speed = GPIO_SPEED_FREQ_LOW;
  HAL_GPIO_Init(OSC_EN_GPIO_Port, &GPIO_InitStruct);

  /*Configure GPIO pins : SPI1_HOLD_Pin SPI1_WP_Pin SPI1_CS_1_Pin SPI2_CS1_Pin
                           SPI3_CS1_Pin USER1_EN_Pin USER_SPI1_EN_Pin */
  GPIO_InitStruct.Pin = SPI1_HOLD_Pin|SPI1_WP_Pin|SPI1_CS_1_Pin|SPI2_CS1_Pin
                          |SPI3_CS1_Pin|USER1_EN_Pin|USER_SPI1_EN_Pin;
  GPIO_InitStruct.Mode = GPIO_MODE_OUTPUT_PP;
  GPIO_InitStruct.Pull = GPIO_NOPULL;
  GPIO_InitStruct.Speed = GPIO_SPEED_FREQ_LOW;
  HAL_GPIO_Init(GPIOC, &GPIO_InitStruct);

  /*Configure GPIO pins : QSPI_CS1_Pin QSPI_CS2_Pin SPI1_CS3_Pin SPI1_CS2_Pin
                           USER2_EN_Pin */
  GPIO_InitStruct.Pin = QSPI_CS1_Pin|QSPI_CS2_Pin|SPI1_CS3_Pin|SPI1_CS2_Pin
                          |USER2_EN_Pin;
  GPIO_InitStruct.Mode = GPIO_MODE_OUTPUT_PP;
  GPIO_InitStruct.Pull = GPIO_NOPULL;
  GPIO_InitStruct.Speed = GPIO_SPEED_FREQ_LOW;
  HAL_GPIO_Init(GPIOA, &GPIO_InitStruct);

  /*Configure GPIO pin : USER4_2_Pin */
  GPIO_InitStruct.Pin = USER4_2_Pin;
  GPIO_InitStruct.Mode = GPIO_MODE_INPUT;
  GPIO_InitStruct.Pull = GPIO_NOPULL;
  HAL_GPIO_Init(USER4_2_GPIO_Port, &GPIO_InitStruct);

  /*Configure GPIO pins : USER4_1_Pin USER3_3_Pin USER3_4_Pin */
  GPIO_InitStruct.Pin = USER4_1_Pin|USER3_3_Pin|USER3_4_Pin;
  GPIO_InitStruct.Mode = GPIO_MODE_INPUT;
  GPIO_InitStruct.Pull = GPIO_NOPULL;
  HAL_GPIO_Init(GPIOB, &GPIO_InitStruct);

  /*Configure GPIO pins : SPI2_CS2_Pin USER1_2_Pin */
  GPIO_InitStruct.Pin = SPI2_CS2_Pin|USER1_2_Pin;
  GPIO_InitStruct.Mode = GPIO_MODE_OUTPUT_PP;
  GPIO_InitStruct.Pull = GPIO_NOPULL;
  GPIO_InitStruct.Speed = GPIO_SPEED_FREQ_LOW;
  HAL_GPIO_Init(GPIOF, &GPIO_InitStruct);

  /*Configure GPIO pins : USER1_1_Pin USER2_4_Pin */
  GPIO_InitStruct.Pin = USER1_1_Pin|USER2_4_Pin;
  GPIO_InitStruct.Mode = GPIO_MODE_INPUT;
  GPIO_InitStruct.Pull = GPIO_NOPULL;
  HAL_GPIO_Init(GPIOG, &GPIO_InitStruct);

  /*Configure GPIO pins : SPI3_CS2_Pin WATCHDOG_Pin GLO_EN_Pin CPU_EN_Pin */
  GPIO_InitStruct.Pin = SPI3_CS2_Pin|WATCHDOG_Pin|GLO_EN_Pin|CPU_EN_Pin;
  GPIO_InitStruct.Mode = GPIO_MODE_OUTPUT_PP;
  GPIO_InitStruct.Pull = GPIO_NOPULL;
  GPIO_InitStruct.Speed = GPIO_SPEED_FREQ_LOW;
  HAL_GPIO_Init(GPIOE, &GPIO_InitStruct);

  /*Configure GPIO pins : I2C4_EN_Pin USER6_EN_Pin */
  GPIO_InitStruct.Pin = I2C4_EN_Pin|USER6_EN_Pin;
  GPIO_InitStruct.Mode = GPIO_MODE_OUTPUT_PP;
  GPIO_InitStruct.Pull = GPIO_NOPULL;
  GPIO_InitStruct.Speed = GPIO_SPEED_FREQ_LOW;
  HAL_GPIO_Init(GPIOB, &GPIO_InitStruct);

  /*Configure GPIO pins : UART3_EN_Pin CAN2_EN_Pin I2C3_EN_Pin CAN1_EN_Pin
                           USER_SPI2_EN_Pin USER5_EN_Pin I2C2_EN_Pin */
  GPIO_InitStruct.Pin = UART3_EN_Pin|CAN2_EN_Pin|I2C3_EN_Pin|CAN1_EN_Pin
                          |USER_SPI2_EN_Pin|USER5_EN_Pin|I2C2_EN_Pin;
  GPIO_InitStruct.Mode = GPIO_MODE_OUTPUT_PP;
  GPIO_InitStruct.Pull = GPIO_NOPULL;
  GPIO_InitStruct.Speed = GPIO_SPEED_FREQ_LOW;
  HAL_GPIO_Init(GPIOD, &GPIO_InitStruct);

  /*Configure GPIO pins : UART2_EN_Pin UART4_EN_Pin UART1_EN_Pin SPI3_EN_Pin
                           SPI2_EN_Pin USER4_EN_Pin USER3_EN_Pin */
  GPIO_InitStruct.Pin = UART2_EN_Pin|UART4_EN_Pin|UART1_EN_Pin|SPI3_EN_Pin
                          |SPI2_EN_Pin|USER4_EN_Pin|USER3_EN_Pin;
  GPIO_InitStruct.Mode = GPIO_MODE_OUTPUT_PP;
  GPIO_InitStruct.Pull = GPIO_NOPULL;
  GPIO_InitStruct.Speed = GPIO_SPEED_FREQ_LOW;
  HAL_GPIO_Init(GPIOG, &GPIO_InitStruct);

  /*Configure GPIO pin : BOOT_Pin */
  GPIO_InitStruct.Pin = BOOT_Pin;
  GPIO_InitStruct.Mode = GPIO_MODE_INPUT;
  GPIO_InitStruct.Pull = GPIO_NOPULL;
  HAL_GPIO_Init(BOOT_GPIO_Port, &GPIO_InitStruct);

}

void Error_Handler(void)
{
}

/************************ (C) COPYRIGHT STMicroelectronics *****END OF FILE****/
